# PIC32MZ1025W104132 device description
Architecture: MIPS; Family: PIC32MZW; Series: PIC32MZW
Registers are 32-bit, read-write, no defined reset value unless marked. A register's access mark holds for its fields unless they carry their own. Offsets are from the block's base; [hi:lo] are bit positions; 'fields as' and 'values as' point back to an identical list.

## UART
Instances: UART 0x1f801600 in periph_pb1a
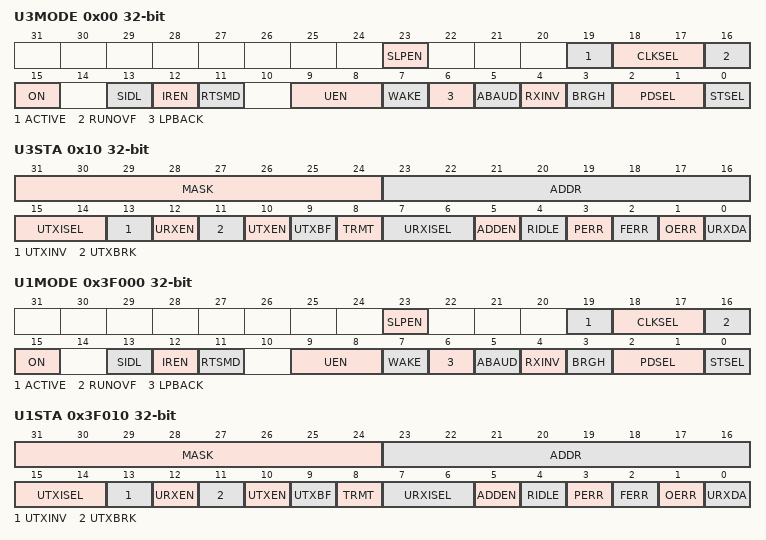
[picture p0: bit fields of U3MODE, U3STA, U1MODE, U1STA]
0x00 U3MODE — UARTx Mode Register
  [23] SLPEN — Run During Sleep Enable bit
    1=UARTx BRG clock runs during Sleep mode; 0=UARTx BRG clock is turned off during Sleep mode
  [19] ACTIVE — UARTx Module Running Status bit
    8=UARTx module is active (UxMODE register should not be updated); 0=UARTx module is not active (UxMODE register can be updated)
  [18:17] CLKSEL — UARTx Module Clock Selection bits
    3=BRG clock is REFCLK1; 2=BRG clock is FRC; 1=BRG clock is SYSCLK; 0=BRG clock is PBCLK1
  [16] RUNOVF — Run During Overflow Condition Mode bit
    2=When an Overflow Error (OERR) condition is detected, the shift register continues to run to remain synchronized; 0=When an Overflow Error (OERR) condition is detected, the shift register stops accepting new data (Legacy mode)
  [15] ON — UARTx Enable bit
    1=UARTx module is enabled. UARTx pins are controlled by UARTx as defined by UEN and UTXEN control bits; 0=UARTx module is disabled. All UARTx pins are controlled by corresponding bits in the PORTx, TRISx, and LATx registers; UARTx power consumption is minimal
  [13] SIDL — Stop in Idle Mode bit
    1=Discontinue operation when device enters Idle mode; 0=Continue operation in Idle mode
  [12] IREN — IrDA Encoder and Decoder Enable bit
    1=IrDA is enabled; 0=IrDA is disabled
  [11] RTSMD — Mode Selection for UxRTS Pin bit
    1=UxRTS pin is in Simplex mode; 0=UxRTS pin is in Flow Control mode
  [9:8] UEN — UARTx Module Enable bits
    3=UxTX, UxRX and UxBCLK pins are enabled and used; 2=UxTX, UxRX, UxCTS and UxRTS pins are enabled and used; 1=UxTX, UxRX and UxRTS pins are enabled and used; UxCTS pin is controlled by corresponding bits in the PORTx register; 0=UxTX and UxRX pins are enabled and used; UxCTS and UxRTS/UxBCLK pins are controlled by corresponding bits in the PORTx register
  [7] WAKE — Enable Wake-up on Start bit Detect During Sleep Mode bit
    1=Wake-up enabled; 0=Wake-up disabled
  [6] LPBACK — UARTx Loopback Mode Select bit
    1=Loopback mode is enabled; 0=Loopback mode is disabled
  [5] ABAUD — Auto-Baud Enable bit
    1=Enable baud rate measurement on the next character requires reception of Sync character (0x55); cleared by hardware upon completion; 0=Baud rate measurement disabled or completed
  [4] RXINV — Receive Polarity Inversion bit
    1=UxRX Idle state is 0; 0=UxRX Idle state is 1
  [3] BRGH — High Baud Rate Enable bit
    1=High-Speed mode 4x baud clock enabled; 0=Standard Speed mode 16x baud clock enabled
  [2:1] PDSEL — Parity and Data Selection bits
    3=9-bit data, no parity; 2=8-bit data, odd parity; 1=8-bit data, even parity; 0=8-bit data, no parity
  [0] STSEL — Stop Selection bit
    1=2 Stop bits; 0=1 Stop bit
0x10 U3STA — UARTx Status and Control Register
  [31:24] MASK — UARTx Address Match Mask bits
    0x1fe=Corresponding ADDRx bits are used to detect the address match; 0=Corresponding ADDRx bits are not used to detect the address match
  [23:16] ADDR
  [15:14] UTXISEL — TX Interrupt Mode Selection bits
    2=Interrupt is generated and asserted while the transmit buffer is empty; 1=Interrupt is generated and asserted when all characters have been transmitted; 0=Interrupt is generated and asserted while the transmit buffer contains at least one empty space
  [13] UTXINV — Transmit Polarity Inversion bit
    1=(If IrDA mode is disabled) UxTX Idle state is 0 / (If IrDA mode is enabled) IrDA encoded UxTX Idle state is 1; 0=(If IrDA mode is disabled) UxTX Idle state is 1 / (If IrDA mode is enabled) IrDA encoded UxTX Idle state is 0
  [12] URXEN — Receiver Enable bit
    1=UARTx receiver is enabled. UxRX pin is controlled by UARTx (if ON = 1); 0=UARTx receiver is disabled. UxRX pin is ignored by the UARTx module
  [11] UTXBRK — Transmit Break bit
    1=Send Break on next transmission. Start bit followed by twelve 0 bits; 0=Break transmission is disabled or completed
  [10] UTXEN — Transmit Enable bit
    1=UARTx transmitter is enabled. UxTX pin is controlled by UARTx (if ON = 1); 0=UARTx transmitter is disabled. Any pending transmission is aborted and buffer is reset
  [9] UTXBF — Transmit Buffer Full Status bit (read-only)
    1=Transmit buffer is full; 0=Transmit buffer is not full, at least one more character can be written
  [8] TRMT — Transmit Shift Register is Empty bit (read-only)
    1=Transmit shift register is empty and transmit buffer is empty (the last transmission has completed); 0=Transmit shift register is not empty
  [7:6] URXISEL — Receive Interrupt Mode Selection bit
    2=Interrupt flag bit is asserted while receive buffer is 3/4 or more full; 1=Interrupt flag bit is asserted while receive buffer is 1/2 or more full; 0=Interrupt flag bit is asserted while receive buffer is not empty (i.e
  [5] ADDEN — Address Character Detect bit (bit 8 of received data = 1)
    1=Address Detect mode is enabled. If 9-bit mode is not selected, this control bit has no effect; 0=Address Detect mode is disabled
  [4] RIDLE — Receiver Idle bit (read-only)
    1=Receiver is Idle; 0=Data is being received
  [3] PERR — Parity Error Status bit (read-only)
    1=Parity error has been detected for the current character; 0=Parity error has not been detected
  [2] FERR — Framing Error Status bit (read-only)
    1=Framing error has been detected for the current character; 0=Framing error has not been detected
  [1] OERR — Receive Buffer Overrun Error Status bit.
    1=Receive buffer has overflowed; 0=Receive buffer has not overflowed
  [0] URXDA — Receive Buffer Data Available bit (read-only)
    1=Receive buffer has data; 0=Receive buffer is empty
0x20 U3TXREG
  [8:0] U3TXREG
0x30 U3RXREG ro
  [8:0] U3RXREG
0x40 U3BRG
  [19:0] BRG — Baud Rate Generator
    1=Divisor value is 1
0x3F000 U1MODE — UARTx Mode Register
  [23] SLPEN — Run During Sleep Enable bit
    values as U3MODE.SLPEN
  [19] ACTIVE — UARTx Module Running Status bit
    values as U3MODE.ACTIVE
  [18:17] CLKSEL — UARTx Module Clock Selection bits
    3=BRG clock is REFCLK1; 2=BRG clock is FRC; 1=BRG clock is SYSCLK; 0=BRG clock is PBCLK3
  [16] RUNOVF — Run During Overflow Condition Mode bit
    values as U3MODE.RUNOVF
  [15] ON — UARTx Enable bit
    values as U3MODE.ON
  [13] SIDL — Stop in Idle Mode bit
    values as U3MODE.SIDL
  [12] IREN — IrDA Encoder and Decoder Enable bit
    1=IrDA is enabled; 0=IrDA is disabled
  [11] RTSMD — Mode Selection for UxRTS Pin bit
    values as U3MODE.RTSMD
  [9:8] UEN — UARTx Module Enable bits
    values as U3MODE.UEN
  [7] WAKE — Enable Wake-up on Start bit Detect During Sleep Mode bit
    1=Wake-up enabled; 0=Wake-up disabled
  [6] LPBACK — UARTx Loopback Mode Select bit
    1=Loopback mode is enabled; 0=Loopback mode is disabled
  [5] ABAUD — Auto-Baud Enable bit
    values as U3MODE.ABAUD
  [4] RXINV — Receive Polarity Inversion bit
    1=UxRX Idle state is 0; 0=UxRX Idle state is 1
  [3] BRGH — High Baud Rate Enable bit
    values as U3MODE.BRGH
  [2:1] PDSEL — Parity and Data Selection bits
    values as U3MODE.PDSEL
  [0] STSEL — Stop Selection bit
    1=2 Stop bits; 0=1 Stop bit
0x3F010 U1STA — UARTx Status and Control Register
  fields as U3STA
0x3F020 U1TXREG
  [8:0] U1TXREG
0x3F030 U1RXREG ro
  [8:0] U1RXREG
0x3F040 U1BRG
  [19:0] BRG — Baud Rate Generator
    1=Divisor value is 1
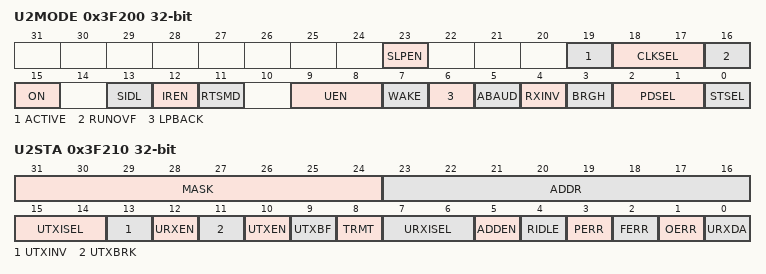
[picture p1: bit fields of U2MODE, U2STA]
0x3F200 U2MODE — UARTx Mode Register
  fields as U1MODE
0x3F210 U2STA — UARTx Status and Control Register
  fields as U3STA
0x3F220 U2TXREG
  [8:0] U2TXREG
0x3F230 U2RXREG ro
  [8:0] U2RXREG
0x3F240 U2BRG
  [19:0] BRG — Baud Rate Generator
    1=Divisor value is 1
